# Real-Time_Clock_2 register map
Vendor: Texas Instruments
Peripheral module from a debugger description file (folder msp430).
Registers are 16-bit, access not given, no defined reset value unless marked. A register's access mark holds for its fields unless they carry their own. Offsets are as the file gives them; lines under a group give offsets from that group; [hi:lo] are bit positions; {n}, {i} and the like mark numbered series; 'fields as' and 'values as' point back to an identical list; <NAME> marks a mode.

## Real-Time_Clock
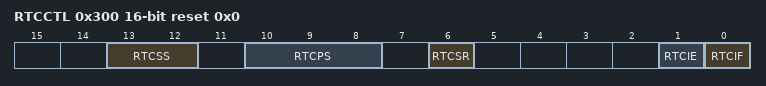
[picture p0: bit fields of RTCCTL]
0x300 RTCCTL rw reset 0x0 — RTC control Register
  [13:12] RTCSS — Low-Power-Counter Clock Source Select Bit: 0
    {v}=Low-Power-Counter Clock Source Select: {v} (v=0..3)
  [10:8] RTCPS — Low-Power-Counter Clock Pre-divider Select Bit: 0
    {v}=Low-Power-Counter Clock Pre-divider Select: {v} (v=0..7)
  [6] RTCSR — Low-Power-Counter Software Reset
  [1] RTCIE — Low-Power-Counter Interrupt Enable
  [0] RTCIF — Low-Power-Counter Interrupt Flag
0x304 RTCIV — RTC interrupt vector
0x308 RTCMOD — RTC moduloRegister
0x30C RTCCNT — RTC counter Register
